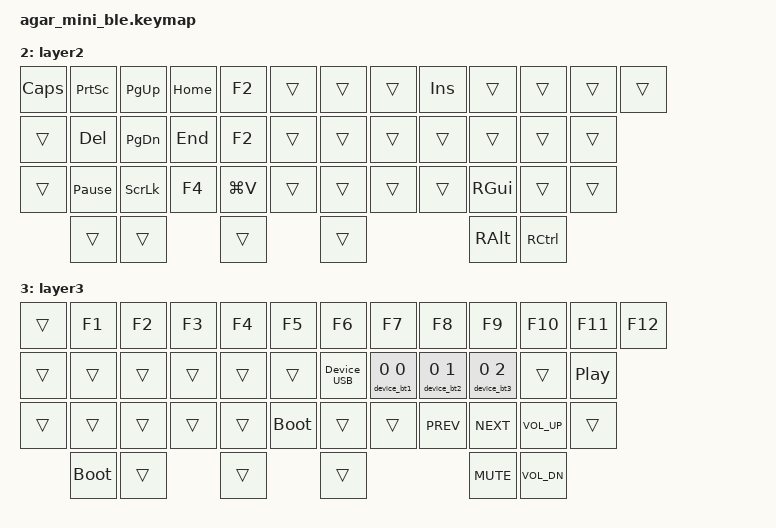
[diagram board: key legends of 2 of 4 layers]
#include <behaviors.dtsi>
#include <dt-bindings/zmk/keys.h>
#include <dt-bindings/zmk/bt.h>
#include <dt-bindings/zmk/mouse.h>
#include "common.keymap"

/ {
    behaviors {
        // [수정] Vial의 Ignore Interrupt와 같은 효과를 주는 오타 방지형 스페이스바
        sk_sp: space_layer_tap {
            compatible = "zmk,behavior-hold-tap";
            label = "SPACE_LAYER_TAP";
            #binding-cells = <2>;
            flavor = "tap-preferred";    // 탭 우선 (빠른 타이핑 시 오타 방지)
            tapping-term-ms = <180>;     // Vial에서 사용하던 180ms 적용
            quick-tap-ms = <125>;        // 연타 시 스페이스 입력 원활화
            bindings = <&mo>, <&kp>;
        };
    };

    // [수정] ESC + BSPC 콤보 (레이어 3인 상태에서만 작동하도록 안전장치)
    combos {
        compatible = "zmk,combos";
        combo_bootloader {
            timeout-ms = <50>;
            key-positions = <0 12>; // ESC(0) + BSPC(12)
            bindings = <&bootloader>;
            layers = <3>; 
        };
    };

    keymap {
        compatible = "zmk,keymap";

        default_layer {
            bindings = <
&gresc         &kp Q  &kp W  &kp E  &kp R  &kp T  &kp Y  &kp U  &kp I  &kp O  &kp P  &mt_tp LGUI BACKSLASH  &kp BSPC
&lt_hp 2 TAB   &kp A  &kp S  &kp D  &kp F  &kp G  &kp H  &kp J  &kp K  &kp L  &kp SEMI              &kp RET
&kp LSHFT      &kp Z  &kp X  &kp C  &kp V  &kp B  &kp N  &kp M  &kp COMMA  &kp DOT  &mt RSHIFT UP_ARROW  &lt_hp 3 RIGHT_ARROW
// [하단열] 6U 레이아웃 5키 인덱스 수정 완료
           &kp LCTRL  &kp LALT   &sk_sp 1 SPACE   &kp RALT   &mo 3
            >;
        };

        layer1 {
            bindings = <
&kp GRAVE  &kp N1  &kp N2  &kp N3          &kp N4          &kp N5           &kp N6            &kp N7             &kp N8  &kp N9     &kp N0             &kp MINUS  &kp EQUAL
&trans     &trans  &trans  &mkp LCLK       &mmv MOVE_UP    &mkp RCLK        &kp LEFT_BRACKET  &kp RIGHT_BRACKET  &trans  &trans     &kp SINGLE_QUOTE   &trans
&trans     &trans  &trans  &mmv MOVE_LEFT  &mmv MOVE_DOWN  &mmv MOVE_RIGHT  &trans            &trans             &trans  &kp SLASH  &trans             &trans
           &trans  &trans                  &trans                           &trans                               &trans
            >;
        };

        layer2 {
            bindings = <
&kp CAPSLOCK  &kp PRINTSCREEN  &kp PAGE_UP     &kp HOME  &kp F2     &trans  &trans  &trans  &kp INSERT  &trans    &trans     &trans  &trans
&trans        &kp DELETE       &kp PAGE_DOWN   &kp END   &kp F2     &trans  &trans  &trans  &trans      &trans    &trans     &trans
&trans        &kp PAUSE_BREAK  &kp SCROLLLOCK  &kp F4    &kp LG(V)  &trans  &trans  &trans  &trans      &kp RGUI  &trans     &trans
              &trans           &trans                    &trans             &trans                      &kp RALT  &kp RCTRL
            >;
        };

        layer3 {
            bindings = <
&trans  &kp F1  &kp F2  &kp F3  &kp F4  &kp F5  &kp F6  &kp F7  &kp F8      &kp F9      &kp F10        &kp F11            &kp F12
&trans  &trans  &trans  &trans  &trans  &trans  &Device_USB  &device_bt1 0 0  &device_bt2 0 1  &device_bt3 0 2  &trans    &kp C_PLAY_PAUSE
&trans  &trans  &trans  &trans  &trans  &bootloader  &trans  &trans  &kp C_PREV  &kp C_NEXT  &kp C_VOL_UP  &trans
        &bootloader  &trans          &trans          &trans                      &kp C_MUTE  &kp C_VOL_DN
            >;
        };

        layer4 { status = "reserved"; };
        layer5 { status = "reserved"; };
        layer6 { status = "reserved"; };
        layer7 { status = "reserved"; };
    };
};
